# MK20F12 register map
Vendor: Freescale Semiconductor, Inc.; Series: Kinetis_K; File version: 1.6
CPU: CM4 r0p1, little endian, no MPU, FPU, VTOR, 4 interrupt priority bits
Registers are 32-bit, read-write, reset 0x0 unless marked. A register's access mark holds for its fields unless they carry their own. Offsets are from the block's base; [hi:lo] are bit positions; {n}, {i} and the like mark numbered series; 'fields as' and 'values as' point back to an identical list.

## PTA — General Purpose Input/Output
Base 0x400FF000; register names take the prefix GPIOA_
0x00 PDOR — Port Data Output Register
  [31:0] PDO — Port Data Output
    0=Logic level 0 is driven on pin, provided pin is configured for general-purpose output; 1=Logic level 1 is driven on pin, provided pin is configured for general-purpose output
0x04 PSOR wo — Port Set Output Register
  [31:0] PTSO — Port Set Output
    0=Corresponding bit in PDORn does not change; 1=Corresponding bit in PDORn is set to logic 1
0x08 PCOR wo — Port Clear Output Register
  [31:0] PTCO — Port Clear Output
    0=Corresponding bit in PDORn does not change; 1=Corresponding bit in PDORn is cleared to logic 0
0x0C PTOR wo — Port Toggle Output Register
  [31:0] PTTO — Port Toggle Output
    0=Corresponding bit in PDORn does not change; 1=Corresponding bit in PDORn is set to the inverse of its existing logic state
0x10 PDIR ro — Port Data Input Register
  [31:0] PDI — Port Data Input
    0=Pin logic level is logic 0 or, is not configured for use by digital function; 1=Pin logic level is logic 1
0x14 PDDR — Port Data Direction Register
  [31:0] PDD — Port data direction
    0=Pin is configured as general-purpose input, for the GPIO function; 1=Pin is configured for general-purpose output, for the GPIO function

## PTB — General Purpose Input/Output
Base 0x400FF040; register names take the prefix GPIOB_
Registers as PTA.

## PTC — General Purpose Input/Output
Base 0x400FF080; register names take the prefix GPIOC_
Registers as PTA; these are added or differ:
0x08 PCOR wo — Port Clear Output Register
  [31:0] PTCO — Port Clear Output
    0=Corresponding bit in PDORn does not change; 1=Corresponding bit in PDORn is cleared to logic 0

## PTD — General Purpose Input/Output
Base 0x400FF0C0; register names take the prefix GPIOD_
Registers as PTA.

## PTE — General Purpose Input/Output
Base 0x400FF100; register names take the prefix GPIOE_
Registers as PTA.

## PTF — General Purpose Input/Output
Base 0x400FF140; register names take the prefix GPIOF_
Registers as PTA.

## SysTick — System timer
Base 0xE000E010; register names take the prefix SYST_
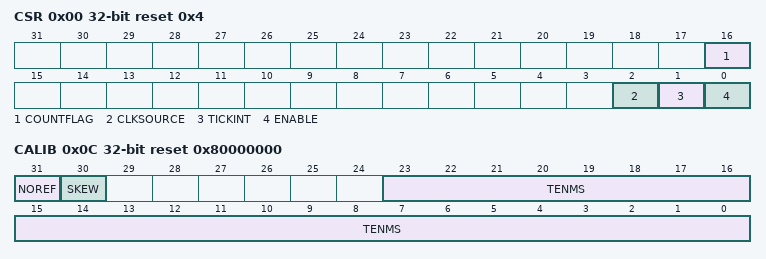
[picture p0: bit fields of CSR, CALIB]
0x00 CSR reset 0x4 — SysTick Control and Status Register
  [16] COUNTFLAG
  [2] CLKSOURCE
    0=external clock; 1=processor clock
  [1] TICKINT
    0=counting down to 0 does not assert the SysTick exception request; 1=counting down to 0 asserts the SysTick exception request
  [0] ENABLE
    0=counter disabled; 1=counter enabled
0x04 RVR — SysTick Reload Value Register
  [23:0] RELOAD — Value to load into the SysTick Current Value Register when the counter reaches 0
0x08 CVR — SysTick Current Value Register
  [23:0] CURRENT — Current value at the time the register is accessed
0x0C CALIB ro reset 0x80000000 — SysTick Calibration Value Register
  [31] NOREF
    0=The reference clock is provided; 1=The reference clock is not provided
  [30] SKEW
    0=10ms calibration value is exact; 1=10ms calibration value is inexact, because of the clock frequency
  [23:0] TENMS — Reload value to use for 10ms timing

## NVIC — Nested Vectored Interrupt Controller
Base 0xE000E100
{0x0+4i} NVICISER{i} (i=0..3) — Interrupt Set Enable Register n
  [31:0] SETENA — Interrupt set enable bits
{0x80+4i} NVICICER{i} (i=0..3) — Interrupt Clear Enable Register n
  [31:0] CLRENA — Interrupt clear-enable bits
{0x100+4i} NVICISPR{i} (i=0..3) — Interrupt Set Pending Register n
  [31:0] SETPEND — Interrupt set-pending bits
{0x180+4i} NVICICPR{i} (i=0..3) — Interrupt Clear Pending Register n
  [31:0] CLRPEND — Interrupt clear-pending bits
{0x200+4i} NVICIABR{i} (i=0..3) — Interrupt Active bit Register n
  [31:0] ACTIVE — Interrupt active flags
{0x300+i} NVICIP{i} 8-bit (i=0..105) — Interrupt Priority Register n
  [7:0] PRI{i} — Priority of interrupt {i}
0xE00 NVICSTIR — Software Trigger Interrupt Register
  [8:0] INTID — Interrupt ID of the interrupt to trigger, in the range 0-239. For example, a value of 0x03 specifies interrupt IRQ3.

## LMEM — Local Memory Controller
Base 0xE0082000; register names take the prefix LMEM_
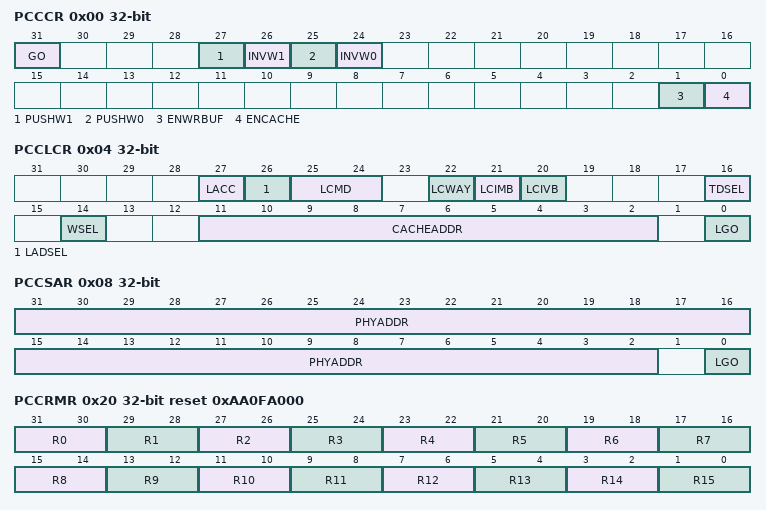
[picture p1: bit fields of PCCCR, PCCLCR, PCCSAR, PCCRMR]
0x00 PCCCR — Cache control register
  [31] GO — Initiate Cache Command
    0=Write: no effect. Read: no cache command active.; 1=Write: initiate command indicated by bits 27-24. Read: cache command active.
  [27] PUSHW1 — Push Way 1
    0=No operation; 1=When setting the GO bit, push all modified lines in way 1
  [26] INVW1 — Invalidate Way 1
    0=No operation; 1=When setting the GO bit, invalidate all lines in way 1
  [25] PUSHW0 — Push Way 0
    0=No operation; 1=When setting the GO bit, push all modified lines in way 0
  [24] INVW0 — Invalidate Way 0
    0=No operation; 1=When setting the GO bit, invalidate all lines in way 0
  [1] ENWRBUF — Enable Write Buffer
    0=Write buffer disabled; 1=Write buffer enabled
  [0] ENCACHE — Cache enable
    0=Cache disabled; 1=Cache enabled
0x04 PCCLCR — Cache line control register
  [27] LACC — Line access type
    0=Read; 1=Write
  [26] LADSEL — Line Address Select
    0=Cache address; 1=Physical address
  [25:24] LCMD — Line Command
    0=Search and read or write; 1=Invalidate; 2=Push; 3=Clear
  [22] LCWAY ro — Line Command Way
  [21] LCIMB ro — Line Command Initial Modified Bit
  [20] LCIVB ro — Line Command Initial Valid Bit
  [16] TDSEL — Tag/Data Select
    0=Data; 1=Tag
  [14] WSEL — Way select
    0=Way 0; 1=Way 1
  [11:2] CACHEADDR — Cache address
  [0] LGO — Initiate Cache Line Command
    0=Write: no effect. Read: no line command active.; 1=Write: initiate line command indicated by bits 27-24. Read: line command active.
0x08 PCCSAR — Cache search address register
  [31:2] PHYADDR — Physical Address
  [0] LGO — Initiate Cache Line Command
    0=Write: no effect. Read: no line command active.; 1=Write: initiate line command indicated by bits CLCR[27:24]. Read: line command active.
0x0C PCCCVR — Cache read/write value register
  [31:0] DATA — Cache read/write Data
0x20 PCCRMR reset 0xAA0FA000 — Cache regions mode register
  [all] fields
    0=Non-cacheable; 1=Non-cacheable; 2=Write-through; 3=Write-back
  [31-2n:30-2n] R{n} (n=0..15) — Region {n} mode
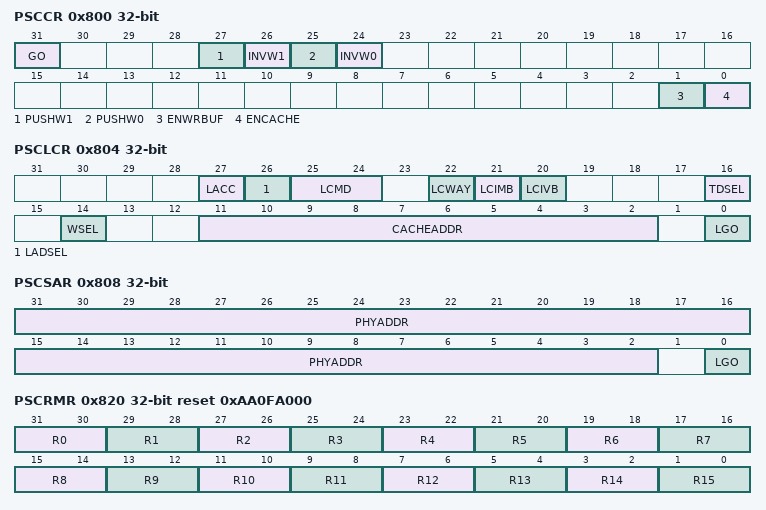
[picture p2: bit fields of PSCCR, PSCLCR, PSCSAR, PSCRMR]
0x800 PSCCR — Cache control register
  fields as PCCCR
0x804 PSCLCR — Cache line control register
  fields as PCCLCR
0x808 PSCSAR — Cache search address register
  fields as PCCSAR
0x80C PSCCVR — Cache read/write value register
  [31:0] DATA — Cache read/write Data
0x820 PSCRMR reset 0xAA0FA000 — Cache regions mode register
  fields as PCCRMR
